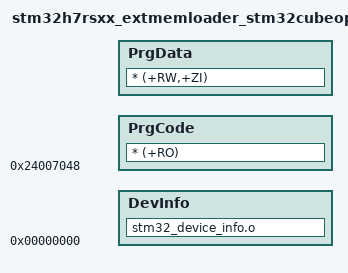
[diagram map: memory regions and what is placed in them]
; **********************************************************************************
; STM32CubeProgrammer ExtMemLoader for OpenBL Linker Control File (scatter-loading)
; **********************************************************************************

;0x24007048 is the address where the ExtMemLoader is loaded
FLASH_LOADER 0x24007048 PI   ; ExtMemLoader Functions
{
  PrgCode +0          ; Code
  {
    * (+RO)
  }
;  0x0401FFFC+0x20000004=0x24020000 where data and bss is loaded
  PrgData +0x0401FFFC          ; Data
  {
    * (+RW,+ZI)
  }
}

;reserved for device information
DEVICE_INFO 0               ; Device Info
{
  DevInfo 0           ; Info structure
  {
    stm32_device_info.o
  }
}
